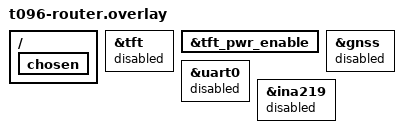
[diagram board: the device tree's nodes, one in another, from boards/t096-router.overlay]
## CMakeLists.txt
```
cmake_minimum_required(VERSION 3.20.0)
include(${CMAKE_CURRENT_SOURCE_DIR}/native-driver.cmake)
include(${CMAKE_CURRENT_SOURCE_DIR}/ble-native-store.cmake)
list(APPEND BOARD_ROOT ${CMAKE_CURRENT_SOURCE_DIR}/../zephcore)
list(APPEND DTS_ROOT ${CMAKE_CURRENT_SOURCE_DIR}/../zephcore)
list(APPEND DTS_ROOT ${CMAKE_CURRENT_SOURCE_DIR})
find_package(Zephyr REQUIRED HINTS $ENV{ZEPHYR_BASE})
include(${CMAKE_CURRENT_SOURCE_DIR}/gnss-native.cmake)
project(mt_zephyr_baseline LANGUAGES C CXX)
include(${CMAKE_CURRENT_SOURCE_DIR}/M119PsaPremasterOverlay.cmake)
set(MT_VENDOR ${CMAKE_CURRENT_SOURCE_DIR}/../zephcore/adapters/bench/vendor)
set(MONO ${CMAKE_CURRENT_SOURCE_DIR}/../zephcore/lib/monocypher)
target_include_directories(app PRIVATE src ${MT_VENDOR} ${MONO} ${CMAKE_CURRENT_SOURCE_DIR}/../zephcore/helpers)
if(CONFIG_MT_T096_ROUTER_ONLY)
  target_sources(app PRIVATE src/BleUnavailable.cpp)
else()
  target_sources(app PRIVATE src/BleTransport.cpp)
endif()
target_sources(app PRIVATE src/main.cpp src/UsbBootloader.cpp src/ZephyrHardware.cpp
  src/security/ConsoleSecurity.cpp
  src/notifications/ZephyrNotification.cpp ../zephcore/helpers/led_gate.c
  src/network/WifiRuntime.cpp src/network/TcpTransport.cpp
  ../zephcore/helpers/battery_curve.c ${MT_VENDOR}/MtCodec.cpp ${MT_VENDOR}/MtSignature.cpp
  ${MONO}/monocypher.c ${MONO}/monocypher-ed25519.c)
# M128 code-size experiment: use Monocypher's existing fixed 12-round loop
# for BLAKE2b in this source file only; algorithm and public interfaces stay unchanged.
set_property(SOURCE "${MONO}/monocypher.c" TARGET_DIRECTORY app
  APPEND PROPERTY COMPILE_DEFINITIONS BLAKE2_NO_UNROLLING)
if(CONFIG_MT_PAGED_SATELLITES)
  set(mt_lfs_adapter "${ZEPHYR_BASE}/subsys/fs/littlefs_fs.c")
  file(SHA256 "${mt_lfs_adapter}" mt_lfs_sha)
  if(NOT mt_lfs_sha STREQUAL "871bcca21b08c4802c2e1a37c608115fa72123113254034b21fba43a4bc1cc3a")
    message(FATAL_ERROR "Check the LittleFS recovery wrappers against the new Zephyr adapter")
  endif()
  set_property(SOURCE "${mt_lfs_adapter}" DIRECTORY "${ZEPHYR_BASE}/subsys/fs"
    APPEND PROPERTY COMPILE_OPTIONS "-include${CMAKE_CURRENT_SOURCE_DIR}/src/companion/PrivateLittlefsRecovery.h")
endif()
target_compile_features(app PRIVATE cxx_std_17)
# The composed Companion dispatch in this TU exceeds the Xtensa separate
# literal-pool range. Keep its literals beside the code on ESP32-S3 only.
if(CONFIG_SOC_ESP32S3)
  zephyr_check_compiler_flag(CXX "-mtext-section-literals" mt_xtensa_text_literals_supported)
  if(NOT mt_xtensa_text_literals_supported)
    message(FATAL_ERROR "ESP32-S3 Companion dispatch requires text-section literals")
  endif()
  set_property(SOURCE "${CMAKE_CURRENT_SOURCE_DIR}/src/main.cpp" TARGET_DIRECTORY app
    APPEND PROPERTY COMPILE_OPTIONS -mtext-section-literals)
endif()
if(CONFIG_MT_SIGNED_BLE_OTA)
  target_sources(app PRIVATE src/update/SignedBleOta.cpp)
endif()
if(CONFIG_MT_GNSS_T096 OR CONFIG_MT_GNSS_XIAO_L76K)
  target_sources(app PRIVATE src/gnss/ZephyrGnss.cpp)
endif()
target_include_directories(app PRIVATE ${CMAKE_CURRENT_SOURCE_DIR}/../zephcore/adapters/sensors)
target_sources_ifdef(CONFIG_MT_MAX30102_OPTICAL app PRIVATE src/stock/telemetry/max30102/ZephyrOptical.cpp src/stock/telemetry/max30102/MaximAlgorithm.cpp)
target_sources_ifdef(CONFIG_MT_ONE_WIRE_TELEMETRY app PRIVATE src/stock/telemetry/ZephyrOneWire.cpp)
target_sources_ifdef(CONFIG_MT_ACCESSORY_SENSORS app PRIVATE src/stock/telemetry/accessory/ZephyrAccessories.cpp)
target_sources_ifdef(CONFIG_MT_MLX90632 app PRIVATE src/stock/telemetry/mlx90632/ZephyrMlx90632.cpp)
target_sources_ifdef(CONFIG_MT_BME680_IAQ app PRIVATE src/stock/telemetry/bme680/ZephyrBme680.cpp
  src/stock/telemetry/bme680/BME680IaqEstimator.cpp)
target_sources_ifdef(CONFIG_MT_SCD4X_ADMIN app PRIVATE src/stock/telemetry/ZephyrScd4xAdmin.cpp)
target_sources_ifdef(CONFIG_MT_ENVIRONMENT_SENSORS app PRIVATE src/environment/ZephyrEnvironment.cpp
  ../zephcore/adapters/sensors/ZephyrEnvSensors.cpp)
target_sources_ifdef(CONFIG_MT_LOCAL_CLOCK app PRIVATE src/clock/LocalTime.cpp)
target_sources_ifdef(CONFIG_MT_DISPLAY app PRIVATE src/ui/Display.cpp)
target_sources_ifdef(CONFIG_MT_BASEUI_GAMES app PRIVATE
  src/stock/ui/games/Snake.cpp src/stock/ui/games/Tetris.cpp
  src/stock/ui/games/ChirpyRunner.cpp src/stock/ui/games/Breakout.cpp)
target_sources_ifdef(CONFIG_MT_SERIAL_MODULE app PRIVATE
  src/serial/SerialEngine.cpp src/serial/ZephyrSerial.cpp
  src/stock/peripherals/NMEAWPL.cpp src/serial/ProtoEngine.cpp src/serial/PositionOutput.cpp src/serial/Ws85Engine.cpp)
if(CONFIG_MT_WIFI_STATION)
  target_include_directories(app PRIVATE ../zephcore/adapters/wifi)
  target_sources(app PRIVATE ../zephcore/adapters/wifi/ZephyrWiFiStation.c)
endif()
if(CONFIG_MT_MQTT_GATEWAY)
  target_sources(app PRIVATE src/network/MqttRuntime.cpp
    src/network/ZephyrMqttPublisherDriver.cpp)
  if(CONFIG_MT_M119_TLS_TEST)
    target_sources(app PRIVATE src/network/M119TlsTestCa.cpp)
  elseif(CONFIG_MQTT_LIB_TLS)
    set(MT_MQTT_CA_DER "" CACHE FILEPATH "One deployment MQTT public self-signed root in DER format")
    set(_mt_ca "${MT_MQTT_CA_DER}")
    set(_mt_ca_sha)
    if(NOT _mt_ca)
      set(_mt_ca "${CMAKE_CURRENT_SOURCE_DIR}/certs/isrg-root-x1.der")
      set(_mt_ca_sha "96bcec06264976f37460779acf28c5a7cfe8a3c0aae11a8ffcee05c0bddf08c6")
    endif()
    set(_mt_ca_header "${CMAKE_CURRENT_BINARY_DIR}/mqtt-trust/mqtt_root_der.generated.h")
    add_custom_command(OUTPUT "${_mt_ca_header}"
      COMMAND "${Python3_EXECUTABLE}" -B "${CMAKE_CURRENT_SOURCE_DIR}/scripts/embed-mqtt-ca.py"
              "${_mt_ca}" "${_mt_ca_header}" ${_mt_ca_sha}
      DEPENDS "${_mt_ca}" "${CMAKE_CURRENT_SOURCE_DIR}/scripts/embed-mqtt-ca.py" VERBATIM)
    target_sources(app PRIVATE src/network/MqttRootCa.cpp "${_mt_ca_header}")
    target_include_directories(app PRIVATE "${CMAKE_CURRENT_BINARY_DIR}/mqtt-trust")
  endif()
endif()

set(MT_PROTO ${CMAKE_CURRENT_SOURCE_DIR}/../zephcore/bench/upstream-differential/source)
file(GLOB MT_PROTO_HEADERS ${MT_PROTO}/*.pb.h)
foreach(HEADER ${MT_PROTO_HEADERS})
  get_filename_component(NAME ${HEADER} NAME)
  configure_file(${HEADER} ${CMAKE_CURRENT_BINARY_DIR}/protobuf/meshtastic/${NAME} COPYONLY)
endforeach()
target_include_directories(app PRIVATE ${CMAKE_CURRENT_BINARY_DIR}/protobuf ${MT_PROTO}/nanopb)
target_sources(app PRIVATE src/stock/platform/ZephyrWatchdog.cpp)
target_sources(app PRIVATE src/stock/modules/StatusMessageModule.cpp src/stock/position/PositionPrecision.cpp src/Protobuf.cpp ${MT_PROTO}/nanopb/pb_common.c ${MT_PROTO}/nanopb/pb_encode.c ${MT_PROTO}/nanopb/pb_decode.c)

include(${CMAKE_CURRENT_SOURCE_DIR}/ble-diagnostics.cmake)

include(${CMAKE_CURRENT_SOURCE_DIR}/pki-groundwork.cmake)
include(${CMAKE_CURRENT_SOURCE_DIR}/controller-lto-profile.cmake)

# BEGIN M104 native Settings admission. Narrow undefined Settings entries.
if(CONFIG_MT_BLE_NATIVE_STORE)
  target_sources(app PRIVATE src/BleSettingsAdmission.cpp)
  zephyr_ld_options(-Wl,--wrap=settings_save_one -Wl,--wrap=settings_delete)
endif()
# END M104 native Settings admission.

target_sources_ifdef(CONFIG_MT_STORE_FORWARD_PSRAM app PRIVATE
  src/modules/StoreForwardWire.cpp src/modules/StoreForwardMemory.cpp)
target_sources_ifdef(CONFIG_MT_GPIO_MODULES app PRIVATE src/modules/ZephyrGpioModule.cpp)

# M176 implementation batch. Optional hardware remains DT/capability gated.
target_sources(app PRIVATE src/modules/BeaconExcursion.cpp src/modules/BeaconTargetRuntime.cpp src/modules/TrafficNodeInfoResponder.cpp src/modules/RangeTestLog.cpp src/input/CannedGpioInput.cpp src/telemetry/CompletionTelemetry.cpp src/power/PowerPolicy.cpp
  src/modules/peripherals/ZephyrPeripherals.cpp src/modules/audio/AudioModule.cpp
  src/modules/audio/Codec2FrameCodec.cpp src/modules/audio/ZephyrI2sAudio.cpp
  src/notifications/ExtendedNotificationController.cpp src/notifications/ZephyrExtendedNotification.cpp)
target_sources_ifdef(CONFIG_MT_INA260 app PRIVATE src/power/ZephyrIna260.c)
target_sources_ifdef(CONFIG_MT_MAX17048 app PRIVATE src/power/ZephyrMax17048.cpp)
target_sources(app PRIVATE src/power/ZephyrPowerBackend.cpp src/power/InaBatterySelector.cpp src/update/ZephyrUpdateBackend.cpp
  src/pki/verification/KeyVerification.cpp src/pki/verification/KeyVerificationService.cpp)
if(CONFIG_ZEPHCORE_AUDIO_CODEC2)
  include(${CMAKE_CURRENT_SOURCE_DIR}/src/modules/audio/Codec2Dependency.cmake)
  target_link_libraries(app PRIVATE codec2)
endif()

if(CONFIG_MT_PKI_FRESH_DOMAIN_ONLY)
  set_property(SOURCE "${MONO}/monocypher.c" "${MONO}/monocypher-ed25519.c" TARGET_DIRECTORY app
    APPEND PROPERTY COMPILE_DEFINITIONS MT_SMALL_CRYPTO_ROUNDS)
  # All app nanopb translation units use memory-backed streams and consume the
  # bool result. Keep the stream ABI identical in the codec and its callers.
  target_compile_definitions(app PRIVATE PB_BUFFER_ONLY PB_NO_ERRMSG)
  if(CONFIG_MT_BASEUI_EMOTES)
    set(emote_source ${CMAKE_CURRENT_SOURCE_DIR}/src/stock/ui/EmoteTable.inc)
    set(emote_packer ${CMAKE_CURRENT_SOURCE_DIR}/scripts/pack-emotes.py)
    set_property(DIRECTORY APPEND PROPERTY CMAKE_CONFIGURE_DEPENDS ${emote_source} ${emote_packer})
    execute_process(COMMAND ${Python3_EXECUTABLE} ${emote_packer} ${emote_source}
      ${CMAKE_CURRENT_BINARY_DIR}/mt_emote_table.h COMMAND_ERROR_IS_FATAL ANY)
    target_compile_definitions(app PRIVATE MT_PACKED_EMOTES)
  endif()
  set(notice_source ${CMAKE_CURRENT_SOURCE_DIR}/src/Companion.h)
  set(notice_packer ${CMAKE_CURRENT_SOURCE_DIR}/scripts/pack-notices.py)
  set_property(DIRECTORY APPEND PROPERTY CMAKE_CONFIGURE_DEPENDS ${notice_source} ${notice_packer})
  execute_process(COMMAND ${Python3_EXECUTABLE} ${notice_packer} ${notice_source}
    ${CMAKE_CURRENT_BINARY_DIR}/mt_notice_table.h COMMAND_ERROR_IS_FATAL ANY)
  target_include_directories(app PRIVATE ${CMAKE_CURRENT_BINARY_DIR})
endif()

if(CONFIG_MT_SIGNED_WIFI_OTA)
  if(NOT MT_OTA_PUBLIC_KEY OR NOT EXISTS "${MT_OTA_PUBLIC_KEY}")
    message(FATAL_ERROR "Signed XIAO OTA requires the MCUboot loader public PEM")
  endif()
  set(_ota_header "${CMAKE_CURRENT_BINARY_DIR}/MtReleaseKey.h")
  add_custom_command(OUTPUT "${_ota_header}"
    COMMAND ${Python3_EXECUTABLE} ${CMAKE_CURRENT_SOURCE_DIR}/scripts/embed-ota-public.py "${MT_OTA_PUBLIC_KEY}" "${_ota_header}"
    DEPENDS ${CMAKE_CURRENT_SOURCE_DIR}/scripts/embed-ota-public.py "${MT_OTA_PUBLIC_KEY}" VERBATIM)
  target_include_directories(app PRIVATE ${CMAKE_CURRENT_BINARY_DIR})
  target_sources(app PRIVATE src/update/SignedOta.cpp src/update/SignedWifiOta.cpp "${_ota_header}")
endif()
```

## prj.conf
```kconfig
CONFIG_CPP=y
CONFIG_STD_CPP17=y
CONFIG_REQUIRES_FULL_LIBC=y
CONFIG_MAIN_STACK_SIZE=8192
CONFIG_SYSTEM_WORKQUEUE_STACK_SIZE=4096
CONFIG_HEAP_MEM_POOL_SIZE=16384
CONFIG_SERIAL=y
CONFIG_GPIO=y
CONFIG_SPI=y
CONFIG_LORA=y
CONFIG_LORA_MODULE_BACKEND_NATIVE=y
CONFIG_LORA_SX126X_NATIVE_SLEEP=n
CONFIG_LORA_SHELL=n
CONFIG_HWINFO=y
CONFIG_ENTROPY_GENERATOR=y
CONFIG_FLASH=y
CONFIG_FLASH_MAP=y
CONFIG_FLASH_PAGE_LAYOUT=y
CONFIG_NVS=y
CONFIG_SETTINGS=y
CONFIG_SETTINGS_NVS=y
CONFIG_PSA_CRYPTO=y
CONFIG_PSA_WANT_KEY_TYPE_AES=y
CONFIG_PSA_WANT_ALG_ECB_NO_PADDING=y
CONFIG_BT=y
CONFIG_BT_PERIPHERAL=y
CONFIG_BT_SMP=y
CONFIG_BT_APP_PASSKEY=y
CONFIG_BT_BONDABLE=y
CONFIG_BT_SETTINGS=y
CONFIG_BT_MAX_CONN=1
CONFIG_BT_DEVICE_NAME_DYNAMIC=y
CONFIG_BT_DEVICE_NAME="ZephTastic ZT"
CONFIG_BT_ATT_PREPARE_COUNT=29
CONFIG_BT_L2CAP_TX_MTU=517
CONFIG_BT_BUF_ACL_RX_SIZE=521
CONFIG_BT_BUF_ACL_TX_SIZE=521
CONFIG_BT_RX_STACK_SIZE=4096
CONFIG_NETWORKING=n
CONFIG_WIFI=n
CONFIG_PM=n
CONFIG_PM_DEVICE=n
CONFIG_LOG=n
CONFIG_ASSERT=y
CONFIG_WATCHDOG=y
CONFIG_REBOOT=y
CONFIG_SHELL=n
CONFIG_CONSOLE=n
CONFIG_PRINTK=n
CONFIG_BOOT_BANNER=n
CONFIG_UART_INTERRUPT_DRIVEN=y

# M104: preserve existing SDK GATT cache/table. Initial bounded key pool.
CONFIG_MT_BLE_NATIVE_STORE=y
CONFIG_BT_BONDABLE_PER_CONNECTION=y
CONFIG_BT_SETTINGS_CCC_LAZY_LOADING=n
CONFIG_BT_MAX_PAIRED=5
CONFIG_BT_KEYS_OVERWRITE_OLDEST=n
CONFIG_BT_GATT_SERVICE_CHANGED=y
CONFIG_BT_GATT_CACHING=y
CONFIG_LTO=n

# USB ingress securely wipes claimed bytes before releasing queue ownership.
CONFIG_RING_BUFFER=y
```

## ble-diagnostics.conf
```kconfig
# Temporary local-only diagnostic image. Does not enable RF or change security.
CONFIG_MT_BLE_DIAGNOSTICS=y
```

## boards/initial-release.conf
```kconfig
# Initial companion/repeater release boundary. The build-local.py
# --initial-release option appends this last and verifies the resolved .config.
CONFIG_MT_TAK_TRACKER=n
```

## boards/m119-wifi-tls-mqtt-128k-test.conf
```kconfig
# M119 temporary test overlay. Combine only with the pinned M118 WiFi/MQTT
# board profile; no network credentials or broker values belong in this file.
# It deliberately selects the one 128 KiB candidate and the default-off test
# hook. Production/T096/ordinary-XIAO configs must not include this overlay.
CONFIG_MT_M119_TLS_TEST=y
CONFIG_MBEDTLS_ENABLE_HEAP=y
CONFIG_ESP_MBEDTLS_HEAP_ALLOC_EXT_RAM=y
CONFIG_MBEDTLS_PSA_STATIC_KEY_SLOTS=y
CONFIG_MBEDTLS_PSA_KEY_SLOT_COUNT=16
CONFIG_MBEDTLS_HEAP_SIZE=131072
```

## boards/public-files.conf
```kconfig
# Requires an existing dedicated application mount at /public.
CONFIG_FILE_SYSTEM=y
CONFIG_FILE_SYSTEM_LITTLEFS=y
CONFIG_MT_RANGE_TEST_LOG=y
CONFIG_MT_RANGE_TEST_LOG_DIR="/public"
CONFIG_MT_PHONE_FILES=y
CONFIG_MT_PHONE_PUBLIC_TREE=y
```

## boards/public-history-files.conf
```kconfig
# Both features explicitly selected. Only this subdirectory is visible to the phone.
CONFIG_MT_RANGE_TEST_LOG_DIR="/zt-history/public"
```

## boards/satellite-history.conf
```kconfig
CONFIG_FILE_SYSTEM=y
CONFIG_FILE_SYSTEM_LITTLEFS=y
CONFIG_MT_SATELLITE_HISTORY=y
CONFIG_FS_LITTLEFS_CACHE_SIZE=64
CONFIG_FS_LITTLEFS_NUM_FILES=2
CONFIG_FS_LITTLEFS_NUM_DIRS=1
```

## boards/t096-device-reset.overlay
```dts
/* Opt-in new-hardware layout. Keep the entire app, settings and bootloader
 * ranges fixed. Old LittleFS devices must use the ordinary profile. The
 * reset owner requires every byte of the original volume erased before its
 * first enrollment and never erases even one byte of a previous filesystem. */
&lfs_partition { reg = <0x000d4000 0x0001f000>; };
/* The base T096 overlay removes fstab, so boot never automounts or formats this volume. */
&flash0 { partitions {
    mt_reset_floor: partition@f3000 { label = "mt-reset-floor"; reg = <0x000f3000 0x1000>; };
}; };
```

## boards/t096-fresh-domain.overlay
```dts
/* Opt-in T096 layout for a new PKI identity. Install only on a unit that
 * passes the full blank-region preflight. Never apply this to a legacy T096.
 * Leaving NVS and /lfs at their original offsets is not an upgrade guarantee:
 * this extended application occupies the historical append journal. */
/delete-node/ &mt_pki_history;
&code_partition { reg = <0x00026000 0x000aa000>; };
```

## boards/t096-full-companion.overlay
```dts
/* Separate first-install layout. Run the offline --full-companion preflight
 * on the original board readback before installing. The new application
 * occupies the previous NVS and part of the former LittleFS volume. */
&code_partition { reg = <0x00026000 0x000b6000>; };
&storage_partition { reg = <0x000dc000 0x00004000>; };
&lfs_partition { reg = <0x000e0000 0x00013000>; };
```

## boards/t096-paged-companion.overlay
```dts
/* Independent first-install geometry for the larger paged companion. */
&code_partition { reg = <0x00026000 0x000b7000>; };
&storage_partition { reg = <0x000dd000 0x00004000>; };
&lfs_partition { reg = <0x000e1000 0x00012000>; };
```

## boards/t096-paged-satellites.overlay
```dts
/* Keep the warm index inside LittleFS metadata. The shared volume then has
 * room for a one-sector public upload while a private table is replaced. */
&mt_sat_fs { cache-size = <128>; };
```

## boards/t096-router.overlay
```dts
/* SPDX-License-Identifier: GPL-3.0-only */
/ { chosen { /delete-property/ zephyr,display; }; };
&tft { status = "disabled"; };
&tft_pwr_enable { /delete-property/ regulator-boot-on; };
&gnss { status = "disabled"; };
&uart0 { status = "disabled"; };
/* The board's optional INA219 is only a connector target. The router uses
 * its internal battery ADC and has no I2C telemetry driver. */
&ina219 { status = "disabled"; };
```

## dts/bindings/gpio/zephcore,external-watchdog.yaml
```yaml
description: External watchdog with a wake input and a pulsed done output
compatible: "zephcore,external-watchdog"
include: base.yaml
properties:
  wake-gpios:
    type: phandle-array
    required: true
  done-gpios:
    type: phandle-array
    required: true
  feed-interval-ms:
    type: int
    required: true
    description: Time between DONE pulses prescribed by the external watchdog
```

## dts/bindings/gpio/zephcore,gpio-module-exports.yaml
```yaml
# SPDX-License-Identifier: MIT

description: |
  Explicit hardware exports for the ZephCore stock GPIO module backend.
  Child reg values are stable wire pin IDs, not GPIO controller offsets.

compatible: "zephcore,gpio-module-exports"
include: base.yaml

properties:
  "#address-cells":
    const: 1
  "#size-cells":
    const: 0

child-binding:
  description: One explicitly exported GPIO-module wire pin.
  properties:
    reg:
      type: array
      required: true
      description: Stable GPIO-module wire pin ID, constrained to 0 through 63.
    gpios:
      type: phandle-array
      required: true
      description: The dedicated GPIO line for this export.
    zephcore,readable:
      type: boolean
      description: Allow input configuration and sampling for this wire pin.
    zephcore,writable:
      type: boolean
      description: Allow output configuration and setting for this wire pin.
    zephcore,pullup:
      type: boolean
      description: Allow input configuration with an internal pull-up.
```

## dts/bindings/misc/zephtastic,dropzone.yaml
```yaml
description: Stock Dropzone status ADC input and optional Lark weather station
compatible: "zephtastic,dropzone"
include: base.yaml
properties:
  io-channels:
    type: phandle-array
    required: true
    description: Dedicated analog input, sampled at the board's configured resolution.
  lark:
    type: phandle
    description: Optional DFRobot Lark I2C child node with its address in reg.
```

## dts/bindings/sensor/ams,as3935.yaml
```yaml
# SPDX-License-Identifier: GPL-3.0-only

description: As3935 stock I2C telemetry accessory
compatible: "ams,as3935"
include: i2c-device.yaml
```

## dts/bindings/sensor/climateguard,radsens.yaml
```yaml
# SPDX-License-Identifier: GPL-3.0-only

description: RadSens static radiation monitor
compatible: "climateguard,radsens"
include: i2c-device.yaml
```

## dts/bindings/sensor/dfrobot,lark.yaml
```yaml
# SPDX-License-Identifier: GPL-3.0-only

description: DFRobot Lark weather station
compatible: "dfrobot,lark"
include: i2c-device.yaml
```

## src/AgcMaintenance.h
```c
#pragma once
#include <cstdint>

namespace mt {
class AgcMaintenance {
    static constexpr uint32_t Minute = 60000;
    static constexpr uint32_t Day = 24 * 60 * Minute;
    uint32_t sampled_ = 0;
    uint32_t successful_ = 0;
    bool pending_ = false;

    bool needed(uint32_t now, uint32_t good) const {
        return !good || now-good >= Minute || !successful_ || now-successful_ >= Day;
    }
public:
    void poll(uint32_t now, uint32_t good, bool idle) {
        if (now-sampled_ < Minute) return;
        sampled_ = now;
        pending_ = idle && needed(now, good);
    }
    bool take(uint32_t now, uint32_t good) {
        const bool due = pending_ && needed(now, good);
        pending_ = false;
        return due;
    }
    void succeeded(uint32_t now) { successful_ = now ? now : 1; }
};
}
```

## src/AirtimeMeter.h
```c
// SPDX-License-Identifier: GPL-3.0-only
#pragma once
#include "tx_window.h"
#include <cstdint>
#include "Observed.h"

namespace mt {
// Trusted monotonic64-bit uptime. UINT64_MAX means unavailable.
using UptimeMsProvider=uint64_t (*)(void *);
struct UptimeClock {UptimeMsProvider get;void *ctx;};

// Estimated airtime of observed clean completions. Uncertain/lost events hide
// the field for a whole hour after their trustworthy terminal time, or after
// the first trustworthy later observation when that time was unavailable.
// The counter retains absolute-minute stock quantization. Quality suppression
// is deliberately stricter than stock fault-path accounting. No RF gate changes.
class AirtimeMeter {
 public:
  bool bind(UptimeClock clock) {
    if(bound_||!clock.get)return false;
    const uint64_t now=clock.get(clock.ctx);
    if(now==UINT64_MAX)return false;
    clock_=clock;bound_=true;
    if(pending_)taint({});
    lastClock_=now;haveClock_=true;
    resolveTaintTime(now);
    // Explicit known idle, rather than a fallback for a failed/absent reading.
    if(window_.record(now,0)!=zt::TxMinuteWindow::Error::None) {
      increment(lost_);taint(now);return false;
    }
    return true;
  }
  bool bound()const{return bound_;}
  void ensureAnchored() {
    if(!bound_||window_.anchored())return;
    auto now=readClock();
    if(now&&window_.record(*now,0)!=zt::TxMinuteWindow::Error::None) {
      increment(lost_);taint(now);
    }
  }
  void noteAcceptedStart(uint32_t estimatedMs) {
    // A lost terminal event cannot be hidden by a second start.
    if(pending_)noteUncertain();
    pending_=true;pendingMs_=estimatedMs;
  }
  void creditPending() {
    if(!pending_)return;
    pending_=false;
    auto now=readClock();
    if(!now) {increment(lost_);taint({});return;}
    if(window_.record(*now,pendingMs_)!=zt::TxMinuteWindow::Error::None) {
      increment(lost_);taint(now);
    }
  }
  void noteUncertain() {
    if(!pending_)return;
    pending_=false;increment(uncertain_);
    taint(readClock());
  }
  bool pending()const{return pending_;}
  uint32_t uncertain()const{return uncertain_;}
  uint32_t lost()const{return lost_;}
  bool anchored()const{return window_.anchored();}
  // Read-time aging mutates the window and remains under Service's owner lock.
  zt::Observed<float> percent() {
    auto now=readClock();
    if(!now||!window_.anchored())return {};
    if(tainted_) {
      if(!taintTimeKnown_||*now<taintAt_||*now-taintAt_<HourMs)return {};
      tainted_=false;
    }
    auto value=window_.percentAt(*now);
    if(!value) {increment(lost_);taint(now);}
    return value;
  }
  const zt::TxMinuteWindow &window()const{return window_;}
 private:
  static constexpr uint64_t HourMs=3600000;
  static void increment(uint32_t &value){if(value<UINT32_MAX)++value;}
  void taint(zt::Observed<uint64_t> now) {
    tainted_=true;taintTimeKnown_=now.has_value();
    if(now)taintAt_=*now;
  }
  void resolveTaintTime(uint64_t now) {
    if(tainted_&&!taintTimeKnown_){taintAt_=now;taintTimeKnown_=true;}
  }
  zt::Observed<uint64_t> readClock() {
    if(!bound_)return {};
    const uint64_t now=clock_.get(clock_.ctx);
    if(now==UINT64_MAX||(haveClock_&&now<lastClock_)) {
      taint({});return {};
    }
    lastClock_=now;haveClock_=true;resolveTaintTime(now);
    return now;
  }
  zt::TxMinuteWindow window_;
  UptimeClock clock_{};
  uint64_t lastClock_=0,taintAt_=0;
  uint32_t pendingMs_=0,uncertain_=0,lost_=0;
  bool bound_=false,pending_=false,haveClock_=false,tainted_=false,taintTimeKnown_=false;
};
}  // namespace mt
```

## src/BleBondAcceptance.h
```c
// SPDX-License-Identifier: GPL-3.0-only
#pragma once
#include <stdint.h>
namespace mt::ble {
// Peer matching uses native ID/address in the caller. Only the captured epoch
// and status cross a store; no key or peer address is retained here.
class BleBondAcceptance {
 uint32_t epoch_=0;bool pin_=false,loaded_=false,paired_=false,stored_=false,failed_=false;
public:
 void begin(uint32_t epoch,bool pin,bool loaded){epoch_=epoch;pin_=pin;loaded_=loaded;paired_=stored_=failed_=false;}
 uint32_t storeBegin()const{return epoch_&&pin_&&!loaded_&&!failed_?epoch_:0;}
 void storeEnd(uint32_t epoch,int result){if(!epoch||epoch!=epoch_)return;if(result)failed_=true;else stored_=true;}
 void paired(bool bonded){if(pin_&&!bonded)failed_=true;else paired_=true;}
 void revoke(){loaded_=stored_=paired_=false;failed_=true;}
 void acceptLoaded(){if(epoch_&&pin_&&!failed_)loaded_=true;}
 bool allowed()const{return epoch_&&!failed_&&(!pin_||loaded_||(paired_&&stored_));}
};
}
```

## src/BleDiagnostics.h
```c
// SPDX-License-Identifier: GPL-3.0-only
#pragma once
#include <stdint.h>
#include <stdbool.h>
#ifdef __cplusplus
extern "C" {
#endif
struct bt_conn;
// Internal diagnostic hooks. Only an opaque connection pointer is compared;
// it is never retained by the observer or rendered in diagnostics.
uint32_t mt_ble_trace_token(struct bt_conn *conn);
void mt_ble_trace_rx(struct bt_conn *conn, uint8_t opcode, bool complete);
void mt_ble_trace_tx(struct bt_conn *conn, uint32_t token, uint8_t opcode, int result);
#ifdef __cplusplus
}
#endif
```

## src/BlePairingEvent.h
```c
// SPDX-License-Identifier: GPL-3.0-only
#pragma once

#include <stdint.h>

namespace mt {
namespace ble {

// Bounded callback-to-main/UI handoff for BLE pairing passkey events (M102).
//
// Concurrency contract:
//   Holds NO internal synchronization. The caller MUST hold the existing BLE
//   session lock (SessionLock) for every call. Pairing/session callbacks never
//   take the application service/UI lock (serviceLock); UI and controller
//   polling are serialized separately under the service lock.
//
// Scope:
//   Pure data handoff. Must NOT call Zephyr, UI, settings, logs, or USB.
//   Stores no timestamps, display strings, bond state, or peer identity.
//
// The session token is the nonzero BLE generation from M101 (BleTransport.cpp):
// incremented on connect, cleared on disconnect.
class BlePairingEvent {
 public:
  struct Snapshot {
    bool active = false;
    uint32_t passkey = 0;
    uint32_t session = 0;
  };

  // begin(0) clears all state. begin(nonzero) replaces the current session and
  // clears any passkey.
  void begin(uint32_t session) {
    session_ = session;
    passkey_ = 0;
    active_ = false;
  }

  // Publishes a passkey for the current session. Requires the current nonzero
  // session to match `session` and `passkey` to be within 0..999999. A
  // stale/zero session or out-of-range PIN returns false and changes nothing.
  bool publishPasskey(uint32_t session, uint32_t passkey) {
    if (session_ == 0 || session != session_ || passkey > 999999u) {
      return false;
    }
    passkey_ = passkey;
    active_ = true;
    return true;
  }

  // Clears the passkey. Succeeds idempotently for the current nonzero session
  // (returns true even if already cleared). A stale/zero session returns false
  // and changes nothing.
  bool clear(uint32_t session) {
    if (session_ == 0 || session != session_) {
      return false;
    }
    passkey_ = 0;
    active_ = false;
    return true;
  }

  // Reads the current state. For the current nonzero session it succeeds even
  // when inactive (so the UI can clear a prior display). A stale/zero session
  // returns false and sets `out` to the default so no old PIN leaks.
  bool snapshot(uint32_t session, Snapshot& out) const {
    if (session_ == 0 || session != session_) {
      out = Snapshot{};
      return false;
    }
    out.active = active_;
    out.passkey = passkey_;
    out.session = session_;
    return true;
  }

 private:
  // Current nonzero BLE session token (0 = no session).
  uint32_t session_ = 0;
  // Passkey, meaningful only when active_ is true.
  uint32_t passkey_ = 0;
  // Whether a passkey is currently published for session_. Tracked separately
  // because a valid PIN can be 0, which cannot be distinguished from "no PIN"
  // by passkey_ alone.
  bool active_ = false;
};

}  // namespace ble
}  // namespace mt
```

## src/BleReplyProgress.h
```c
// SPDX-License-Identifier: GPL-3.0-only
// BleReplyProgress.h - RAM-only contiguous read coverage tracker for a
// BLE reply drain window. Caller serializes access. Tracks observed
// contiguous read coverage only (not peer receipt, security, durability).
#ifndef MT_BLE_REPLY_PROGRESS_H
#define MT_BLE_REPLY_PROGRESS_H

#include <stdint.h>
#include <stddef.h>

namespace mt {
namespace ble {

class BleReplyProgress {
public:
    enum class State : uint8_t { Idle, Waiting, Drained, Expired, Cancelled };

    bool begin(uint32_t session, size_t length, uint64_t now, uint32_t timeoutMs) {
        if (state_ != State::Idle) return false;
        if (session == 0u) return false;
        if (length < 1u || length > 512u) return false;
        if (timeoutMs < 1u || timeoutMs > 10000u) return false;
        if (now > UINT64_MAX - static_cast<uint64_t>(timeoutMs)) return false;
        session_ = session;
        length_ = length;
        start_ = now;
        deadline_ = now + static_cast<uint64_t>(timeoutMs);
        covered_ = 0u;
        state_ = State::Waiting;
        return true;
    }

    bool read(uint32_t session, size_t offset, size_t count, uint64_t now) {
        if (state_ != State::Waiting) return false;
        if (session == 0u || session != session_) return false;
        if (now < start_ || now >= deadline_) { state_ = State::Expired; return false; }
        if (count == 0u) return false;
        if (offset > covered_) return false;
        if (offset > length_) return false;
        if (count > length_ - offset) return false;
        const size_t end = offset + count;
        if (end > covered_) covered_ = end;
        if (covered_ == length_) state_ = State::Drained;
        return true;
    }

    State poll(uint64_t now) {
        if (state_ == State::Waiting && (now < start_ || now >= deadline_))
            state_ = State::Expired;
        return state_;
    }

    void cancel(uint32_t session) {
        if (state_ == State::Waiting && session != 0u && session == session_)
            state_ = State::Cancelled;
    }

    void reset() {
        state_ = State::Idle;
        session_ = 0u;
        length_ = 0u;
        start_ = 0u;
        deadline_ = 0u;
        covered_ = 0u;
    }

    State state() const { return state_; }
    size_t covered() const { return covered_; }

private:
    State state_ = State::Idle;
    uint32_t session_ = 0u;
    size_t length_ = 0u;
    uint64_t start_ = 0u;
    uint64_t deadline_ = 0u;
    size_t covered_ = 0u;
};

}  // namespace ble
}  // namespace mt

#endif  // MT_BLE_REPLY_PROGRESS_H
```

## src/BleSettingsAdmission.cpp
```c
// SPDX-License-Identifier: GPL-3.0-only
#include "BleSettingsAdmission.h"
#include <zephyr/kernel.h>
#include <zephyr/sys/atomic.h>
#include <errno.h>
#include <limits.h>
#include <string.h>

namespace mt::ble::store {
namespace {
K_MUTEX_DEFINE(mutex);
K_SEM_DEFINE(signal,0,1);
enum class Phase:uint8_t {Idle,Waiting,Prepared,Running,Done};
Phase phase=Phase::Idle;
k_tid_t mainThread=nullptr,bootOwner=nullptr,owner=nullptr,sessionOwner=nullptr;
uint32_t serial=0,token=0;
uint64_t deadline=0;
unsigned depth=0,sessionDepth=0;
int terminal=0;
bool initialized=false,strictLoad=false,loaded=false,sealed=false;
atomic_t closed=1,poison=0,health=0;
constexpr uint64_t AdmissionMs=3000;
struct Lock {Lock(){k_mutex_lock(&mutex,K_FOREVER);}~Lock(){k_mutex_unlock(&mutex);}};
void publish(){atomic_set(&health,sealed&&!atomic_get(&poison));atomic_set(&closed,atomic_get(&poison)||!sealed||phase!=Phase::Idle);}
void poisonLocked(int result){if(result)atomic_set(&poison,1);publish();}
void retire(){phase=Phase::Idle;owner=nullptr;token=0;depth=0;deadline=0;publish();}
int enter(bool deletion) {
 (void)deletion;
 const auto self=k_current_get();
 const uint64_t started=uint64_t(k_uptime_get());
 if(started>UINT64_MAX-AdmissionMs){fail(-EOVERFLOW);return -EOVERFLOW;}
 const uint64_t expires=started+AdmissionMs;
 // Other native callers wait for the single slot before any Settings lock.
 // Their arguments remain on their own stacks; no native I/O is resubmitted.
 for(;;) {
  {
   Lock lock;
   if(!initialized||atomic_get(&poison))return -EIO;
   if(sessionOwner==self&&sessionDepth){poisonLocked(-EDEADLK);return -EDEADLK;}
   if(self==bootOwner) {
    // Strict load can request invalid-key cleanup under the Settings mutex.
    // Refuse it rather than entering a new wait or modifying uncertain bytes.
    if(strictLoad){poisonLocked(-EACCES);return -EACCES;}
    return 0;
   }
   if(phase==Phase::Running&&owner==self){++depth;return 0;}
   if(self==mainThread){poisonLocked(-EDEADLK);return -EDEADLK;}
   const uint64_t now=uint64_t(k_uptime_get());
   if(now<started||now>=expires){poisonLocked(-ETIMEDOUT);return -ETIMEDOUT;}
   if(phase==Phase::Idle) {
    if(serial==UINT32_MAX){poisonLocked(-EOVERFLOW);return -EOVERFLOW;}
    token=++serial;deadline=expires;owner=self;phase=Phase::Waiting;publish();break;
   }
  }
  (void)k_sem_take(&signal,K_MSEC(5));
 }
 for(;;) {
  {
   Lock lock;
   if(owner!=self)return -EIO;
   // After grant the caller owns the operation; its arguments cannot expire.
   // Admission timeout never cancels an operation already granted.
   if(phase==Phase::Running){depth=1;return 0;}
   if(phase!=Phase::Waiting&&phase!=Phase::Prepared)return -EIO;
   const uint64_t now=uint64_t(k_uptime_get());
   if(atomic_get(&poison)||now>=deadline||now<deadline-AdmissionMs){
    const int result=atomic_get(&poison)?-EIO:-ETIMEDOUT;
    poisonLocked(result);retire();return result;
   }
  }
  (void)k_sem_take(&signal,K_MSEC(5));
 }
}
void leave(int result) {
 Lock lock;
 poisonLocked(result);
 if(k_current_get()==bootOwner)return;
 if(phase!=Phase::Running||owner!=k_current_get()||!depth){poisonLocked(-EIO);return;}
 if(result&&!terminal)terminal=result;
 if(--depth==0){phase=Phase::Done;publish();}
}
}
void initialize(){Lock lock;if(initialized)return;initialized=true;mainThread=k_current_get();publish();}
bool beginBoot(bool safe){Lock lock;if(!initialized||k_current_get()!=mainThread||!safe||bootOwner||phase!=Phase::Idle){poisonLocked(-EIO);return false;}bootOwner=mainThread;strictLoad=true;return true;}
// Pre-stack offline deletion. Payload and advertising stay closed through the
// following cold boot. Runtime grant paths cannot enter the boot owner.
bool beginDeviceResetErase(bool safe){
 Lock lock;
 if(!safe||!initialized||k_current_get()!=mainThread||bootOwner||phase!=Phase::Idle||
    loaded||sealed||atomic_get(&poison))return false;
 bootOwner=mainThread;strictLoad=false;return true;
}
bool prepareBootCommit(){
 Lock lock;
 if(!initialized||k_current_get()!=mainThread||bootOwner!=mainThread||!strictLoad||loaded||sealed||phase!=Phase::Idle||atomic_get(&poison)){
  poisonLocked(-EACCES);return false;
 }
 // Backend reads and h_set validation are complete. Native h_commit may now
 // write the GATT hash/SC state under the existing Settings mutex. Readiness
 // still waits for the whole Settings API and identity work settlement.
 strictLoad=false;return true;
}
void bootLoadComplete(int result){Lock lock;if(bootOwner!=k_current_get()){poisonLocked(-EIO);return;}if(!result&&strictLoad)result=-EACCES;strictLoad=false;loaded=result==0;poisonLocked(result);}
void endBoot(int result){Lock lock;if(bootOwner!=k_current_get()){poisonLocked(-EIO);return;}bootOwner=nullptr;strictLoad=false;poisonLocked(result);}
void sealBootIfQuiet(bool pending){Lock lock;if(k_current_get()==mainThread&&loaded&&!bootOwner&&!pending&&phase==Phase::Idle&&!atomic_get(&poison))sealed=true;publish();}
bool payloadAllowed(){return atomic_get(&closed)==0;}
bool healthy(){return atomic_get(&health)!=0;}
bool failed(){return atomic_get(&poison)!=0;}
bool waiting(){Lock lock;return phase==Phase::Waiting;}
void fail(int result){Lock lock;poisonLocked(result?result:-EIO);}
void sessionEntered(){Lock lock;const auto self=k_current_get();if(sessionDepth&&sessionOwner!=self){poisonLocked(-EDEADLK);return;}sessionOwner=self;++sessionDepth;}
void sessionLeft(){Lock lock;if(sessionOwner!=k_current_get()||!sessionDepth){poisonLocked(-EIO);return;}if(!--sessionDepth)sessionOwner=nullptr;}
int invoke(bool deletion,Operation operation,void *context){
 if(!operation){fail(-EINVAL);return -EINVAL;}
 (void)deletion;
 const int admitted=enter(deletion);if(admitted)return admitted;
 const int result=operation(context);leave(result);return result;
}
uint32_t pendingToken(){Lock lock;return phase==Phase::Waiting?token:0;}
bool prepare(uint32_t requested){Lock lock;const uint64_t now=uint64_t(k_uptime_get());if(!requested||phase!=Phase::Waiting||token!=requested||atomic_get(&poison)||now>=deadline||now<deadline-AdmissionMs)return false;phase=Phase::Prepared;publish();return true;}
bool grant(uint32_t requested){Lock lock;const uint64_t now=uint64_t(k_uptime_get());if(!requested||phase!=Phase::Prepared||token!=requested||atomic_get(&poison)||now>=deadline||now<deadline-AdmissionMs)return false;phase=Phase::Running;depth=0;terminal=0;publish();return true;}
bool cancel(uint32_t requested,int result){
 {Lock lock;if(!requested||token!=requested||(phase!=Phase::Waiting&&phase!=Phase::Prepared))return false;poisonLocked(result?result:-ECANCELED);retire();}
 wake();return true;
}
bool active(){Lock lock;return phase==Phase::Prepared||phase==Phase::Running||phase==Phase::Done;}
bool completed(uint32_t &out,int &result){Lock lock;if(phase!=Phase::Done)return false;out=token;result=terminal;return true;}
void settle(uint32_t requested,int result){Lock lock;if(phase!=Phase::Done||token!=requested){poisonLocked(-EIO);return;}poisonLocked(result);retire();}
void reject(uint32_t requested,int result){Lock lock;if(phase==Phase::Waiting&&token==requested){poisonLocked(result?result:-EIO);} }
void wake(){k_sem_give(&signal);}
}

// GNU --wrap catches host-settings.c's undefined public Settings references.
// An internal settings_delete -> settings_save_one call may bypass wrapping;
// the outer delete already owns admission. If it does wrap, invoke nests.
extern "C" int __real_settings_save_one(const char *,const void *,size_t);
extern "C" int __real_settings_delete(const char *);
namespace {
bool guarded(const char *name){return name&&(!strncmp(name,"bt/",3)||!strncmp(name,"mtble/gatt/",11));}
struct Save {const char *name;const void *value;size_t size;};
int save(void *p){const auto &s=*static_cast<Save *>(p);return __real_settings_save_one(s.name,s.value,s.size);}
int erase(void *p){return __real_settings_delete(static_cast<const char *>(p));}
}
extern "C" int __wrap_settings_save_one(const char *name,const void *value,size_t size){
 // Main excludes all its MT writers for the complete granted interval. This
 // also refuses an unexpected external MT writer before it can take Settings.
 if(!guarded(name))return mt::ble::store::active()?-EBUSY:__real_settings_save_one(name,value,size);
 Save args{name,value,size};return mt::ble::store::invoke(!value||!size,save,&args);
}
extern "C" int __wrap_settings_delete(const char *name){
 if(!guarded(name))return mt::ble::store::active()?-EBUSY:__real_settings_delete(name);
 return mt::ble::store::invoke(true,erase,const_cast<char *>(name));
}

#if defined(CONFIG_MT_BLE_NATIVE_STORE)
// Source-owned Settings seam. Other subtrees retain the weak default behavior.
extern "C" int zt_settings_prepare_commit(const char *subtree){
 if(!subtree||strcmp(subtree,"bt"))return 0;
 return mt::ble::store::prepareBootCommit()?0:-EACCES;
}
#endif
```

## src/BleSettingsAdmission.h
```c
// SPDX-License-Identifier: GPL-3.0-only
#pragma once
#include <stdint.h>

namespace mt::ble::store {
// RAM-only except invoke(), which executes the caller's original operation.
// No key/value or peer address is retained by this coordinator.
void initialize();
bool beginBoot(bool nativeQuiescent);
bool beginDeviceResetErase(bool nativeQuiescent);
// Called only after all bt backend/h_set reads validate, before native commit.
// Does not mark the store loaded or open payload/advertising gates.
bool prepareBootCommit();
void bootLoadComplete(int result);
void endBoot(int result);
void sealBootIfQuiet(bool nativeIdentityWorkPending);
bool payloadAllowed();
bool healthy();
bool failed();
bool waiting();
void fail(int result);
void sessionEntered();
void sessionLeft();
using Operation=int(*)(void *);
int invoke(bool deletion,Operation operation,void *context);
uint32_t pendingToken();
bool prepare(uint32_t token);
bool grant(uint32_t token);
// Retire only a pre-grant token. A Running operation retains its caller/lease.
bool cancel(uint32_t token,int result);
bool active();
bool completed(uint32_t &token,int &result);
void settle(uint32_t token,int restoreResult);
void reject(uint32_t token,int result);
void wake();
}
```

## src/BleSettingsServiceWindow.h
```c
// SPDX-License-Identifier: GPL-3.0-only
#pragma once
#include "BleSettingsAdmission.h"
#include <errno.h>

namespace mt::ble {
// pollLocked runs only in main with serviceLock held. No stack/Settings calls.
template<class Service,class Radio> class BleSettingsServiceWindow {
 Service &service_;Radio &radio_;bool held_=false,receiving_=false,armed_=false,cancelled_=false;
 uint32_t prepared_=0;
 int restore(uint32_t now) {
  if(!receiving_)return armed_?-EIO:0;
  if(service_.faulted()||!service_.config.provisioned()||!service_.start(false,now)){service_.stop();return -EIO;}
  if(armed_&&(!service_.normalMode()||!service_.txAllowed()||!service_.config.txEnabled())){service_.stop();return -EIO;}
  if(!service_.armEndpoint(armed_)||service_.faulted()){service_.stop();return -EIO;}
  return 0;
 }
public:
 BleSettingsServiceWindow(Service &service,Radio &radio):service_(service),radio_(radio){}
 // Main calls only after serviceLock is released. The waiting caller cannot
 // execute a Prepared token even if its semaphore timeout wakes it first.
 void grantUnlocked(){if(prepared_){cancelled_=!store::grant(prepared_);if(cancelled_)(void)store::cancel(prepared_,-ETIMEDOUT);prepared_=0;store::wake();}}
 bool pollLocked(uint64_t now) {
  if(held_) {
   if(cancelled_){const int restored=restore(uint32_t(now));held_=cancelled_=false;store::fail(restored?restored:-ETIMEDOUT);return false;}
   uint32_t token=0;int result=0;
   if(!store::completed(token,result))return true;
   const int restored=restore(uint32_t(now));held_=false;
   store::settle(token,restored);return false;
  }
  const uint32_t token=store::pendingToken();if(!token)return false;
  if(store::failed()){store::reject(token,-EIO);return false;}
  if(!service_.storageStopSafe()||radio_.busy())return false;
  receiving_=service_.receiving();armed_=service_.endpointArmed();
  const int paused=service_.pauseForStorage();
  if(paused){if(paused!=-EBUSY||service_.faulted())store::reject(token,-EIO);return false;}
  const bool safe=!service_.faulted()&&service_.storageQuiescent()&&radio_.ready()&&radio_.health()==0;
  if(safe&&store::prepare(token)){prepared_=token;held_=true;return true;}
  // Deadline/cancel may have won while native RX was being joined. No caller
  // receives a late grant; restore the RF state even though no I/O occurred.
  const int restored=restore(uint32_t(now));
  if(!safe||restored)store::reject(token,-EIO);
  return false;
 }
};
}
```

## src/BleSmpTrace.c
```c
// SPDX-License-Identifier: GPL-3.0-only
// Opt-in observer of pinned host boundaries. No buffer ownership is acquired,
// no arguments are changed, and no pairing material is copied or inspected.
#include <zephyr/bluetooth/conn.h>
#include <zephyr/bluetooth/l2cap.h>
#include <zephyr/sys/byteorder.h>
#include "conn_internal.h"
#include "l2cap_internal.h"
#include "BleDiagnostics.h"

int __real_bt_l2cap_send_pdu(struct bt_l2cap_le_chan *, struct net_buf *, bt_conn_tx_cb_t, void *);
void __real_bt_l2cap_recv(struct bt_conn *, struct net_buf *, bool);

int __wrap_bt_l2cap_send_pdu(struct bt_l2cap_le_chan *chan, struct net_buf *buf,
                           bt_conn_tx_cb_t cb, void *user_data)
{
    struct bt_conn *conn = NULL;
    uint32_t token = 0;
    uint8_t opcode = 0;
    if (chan && chan->tx.cid == BT_L2CAP_CID_SMP && buf && buf->len) {
        conn = chan->chan.conn;
        token = mt_ble_trace_token(conn);
        opcode = buf->data[0];
    }
    // Ownership can transfer here; never dereference chan or buf afterwards.
    int result = __real_bt_l2cap_send_pdu(chan, buf, cb, user_data);
    if (token) {
        mt_ble_trace_tx(conn, token, opcode, result);
    }
    return result;
}

void __wrap_bt_l2cap_recv(struct bt_conn *conn, struct net_buf *buf, bool complete)
{
    if (buf && buf->len >= BT_L2CAP_HDR_SIZE &&
        sys_get_le16(buf->data + 2) == BT_L2CAP_CID_SMP) {
        // conn.c reassembles ACL fragments before complete=true. Incomplete or
        // length-inconsistent PDUs count separately, without reading an opcode.
        bool full = complete && buf->len > BT_L2CAP_HDR_SIZE &&
                    sys_get_le16(buf->data) == buf->len - BT_L2CAP_HDR_SIZE;
        mt_ble_trace_rx(conn, full ? buf->data[BT_L2CAP_HDR_SIZE] : 0, full);
    }
    __real_bt_l2cap_recv(conn, buf, complete);
}
```

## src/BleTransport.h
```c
// SPDX-License-Identifier: GPL-3.0-only
#pragma once
#include <stddef.h>
#include <stdint.h>
#include "BluetoothSettings.h"
#include "BlePairingEvent.h"
#if defined(CONFIG_MT_SIGNED_BLE_OTA)
struct bt_conn;
#endif
namespace mt::ble {
#if defined(CONFIG_MT_SIGNED_BLE_OTA)
bool otaPolicyReady();
bool beginOta();
bt_conn *otaDisconnectTarget(uint32_t &epoch);
// A retained epoch may buffer its next write in RAM during a healthy native
// Settings lease. A new peer must always enter through an idle store.
uint32_t otaSession(bt_conn *conn,uint32_t retained=0);
// Grant processing only for an authorized epoch and an idle store. A caller
// performing a stack operation may request a referenced peer.
// -EAGAIN identifies the same authorized peer during a temporary store lease.
int otaAccess(uint32_t session,bt_conn **peer=nullptr);
#endif
struct Packet {uint32_t session;uint16_t length;
#if defined(CONFIG_MT_STOCK_IDENTITY_IMPORT)
  bool stockImportAuthenticated=false;
#endif
  uint8_t bytes[512];};
struct SecurityStatus {bool connected=false,pending=false;int request=0;uint8_t level=0,error=0;};
int init(uint32_t node);
int init(uint32_t node,const mt::BluetoothSettings &settings,bool settingsReady);
// Boot-only stack/settings preparation, with no advertising or payload policy
// activation. This enables the ESP controller entropy source before PKI opens.
// Main publishes final application readiness through requestConfiguration().
int prepareBoot(uint32_t node,const mt::BluetoothSettings &settings,bool settingsReady);
// RAM-only staging; safe while the application service mutex is held. poll()
// applies changes outside that mutex and closes the previous session first.
bool requestConfiguration(const mt::BluetoothSettings &settings,bool settingsReady);
// Single local-BLE Admin transaction. begin runs inside validated dispatch;
// journal work runs only after dispatch returns. All APIs below are RAM-only.
bool beginAdmin(uint32_t token);
bool adminBusy();
bool stageAdminResult(const uint8_t *framed,size_t n,uint32_t token);
// True means next policy was accepted, not that the peer received the result.
bool finishAdminConfiguration(const mt::BluetoothSettings &settings,bool settingsReady,
                              uint32_t token,bool replyAllowed);
bool ready();
#if defined(CONFIG_MT_PAXCOUNTER_WIFI_ESP32)
bool paxRadioIdle();
#endif
bool connected();
bool disconnected();
uint32_t session();
#if defined(CONFIG_MT_STOCK_IDENTITY_IMPORT)
bool stockImportLink(uint32_t token);
bool prepareHeldImportEntropy();
#endif
// Ephemeral last-attempt diagnostics, containing no peer identity or key.
SecurityStatus security();
BlePairingEvent::Snapshot pairing();
#if defined(CONFIG_MT_BLE_DIAGNOSTICS)
// Optional local-only, RAM-only pairing-stage report.
size_t diagnostics(char *out,size_t capacity);
#endif
bool receive(Packet &p);
// The callback runs under the session mutex. Call only with the service mutex
// already held; connection callbacks must never acquire the service mutex.
bool dispatch(const Packet &p,void (*callback)(const Packet &,void *),void *context);
bool send(const uint8_t *framed,size_t n,uint32_t session,bool idleOnly=false);
// Main-owned ingress admission. Closing blocks new ToRadio and DFU writes but
// preserves packets already accepted into the owner queue. The gate survives
// BLE session reset/reconnect; only an explicit reopen changes it back.
void setIngressOpen(bool open);
unsigned pendingInput();
#if defined(CONFIG_MT_BLE_LOG_RADIO)
struct LogRadioValue {uint8_t size=0;uint8_t bytes[64]{};};
void setLogRadioEnabled(bool enabled);
uint32_t logRadioSession();
void publishLogRadio(uint32_t token,const LogRadioValue &value);
#endif
void poll();
// Buttonless Nordic DFU only. Main publishes a quiescence/admission window;
// the GATT callback merely records an encrypted, indicated session request.
// takeDfuRequest runs under the normal Service -> session lock order and never
// performs a reset or storage operation. Unsupported builds always return false.
void setDfuWindow(bool ready);
bool takeDfuRequest();
// Install once at startup. The callback must be ISR-safe/nonblocking and must
// never take Service or Settings locks (for example k_sem_give only).
void setActivityWake(void (*wake)());
}
```
